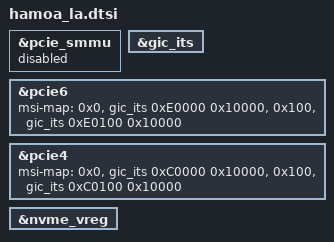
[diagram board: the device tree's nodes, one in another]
// SPDX-License-Identifier: BSD-3-Clause
/*
 * Copyright (c) Qualcomm Technologies, Inc. and/or its subsidiaries.
 */

#include "x1e80100.dtsi"

&pcie_smmu {
	status = "disabled";
};

&gic_its {
	status ="okay";
};

&pcie6 {
	msi-map = <0x0 &gic_its 0xE0000 0x10000>,
		  <0x100 &gic_its 0xE0100 0x10000>; /* 32 event IDs */

	/delete-property/ iommu-map;
};

&pcie4 {
	msi-map = <0x0 &gic_its 0xC0000 0x10000>,
		  <0x100 &gic_its 0xC0100 0x10000>; /* 32 event IDs */

	/delete-property/ iommu-map;
};

&nvme_vreg {
	/delete-property/ regulator-boot-on;
};

